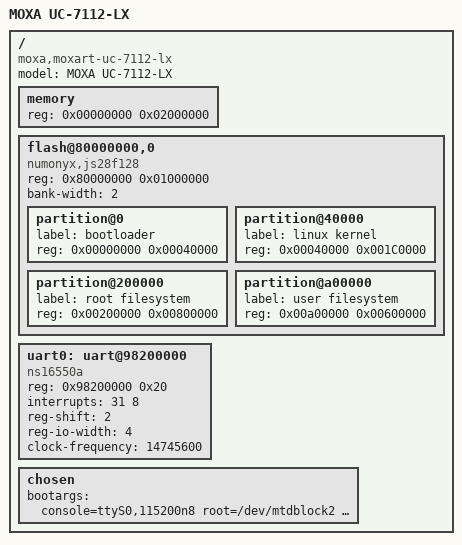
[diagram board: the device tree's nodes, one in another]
/* moxart-uc7112lx.dts - Device Tree file for MOXA UC-7112-LX
 *
 * Copyright (C) 2013 Jonas Jensen <jonas.jensen@gmail.com>
 *
 * Licensed under GPLv2 or later.
 */

/dts-v1/;
/include/ "moxart.dtsi"

/ {
	model = "MOXA UC-7112-LX";
	compatible = "moxa,moxart-uc-7112-lx", "moxa,moxart";

	memory {
		/* SAMSUNG K4S561632J-UC75 */
		device_type = "memory";
		reg = <0x00000000 0x02000000>;
	};

	flash@80000000,0 {
		/* JS28F128 J3D75 A9087684
		 * Numonyx Embedded Flash Memory (J3 v. D)
		 */
		compatible = "numonyx,js28f128", "cfi-flash";
		reg = <0x80000000 0x01000000>;
		bank-width = <2>;
		#address-cells = <1>;
		#size-cells = <1>;
		partition@0 {
			label = "bootloader";
			reg = <0x00000000 0x00040000>;
		};
		partition@40000 {
			label = "linux kernel";
			reg = <0x00040000 0x001C0000>;
		};
		partition@200000 {
			label = "root filesystem";
			reg = <0x00200000 0x00800000>;
		};
		partition@a00000 {
			label = "user filesystem";
			reg = <0x00a00000 0x00600000>;
		};
	};

	uart0: uart@98200000 {
		compatible = "ns16550a";
		reg = <0x98200000 0x20>;
		interrupts = <31 8>;
		reg-shift = <2>;
		reg-io-width = <4>;
		clock-frequency = <14745600>;
		status = "okay";
	};

	chosen {
		bootargs = "console=ttyS0,115200n8 root=/dev/mtdblock2 rootfstype=jffs2 rw";
	};
};
